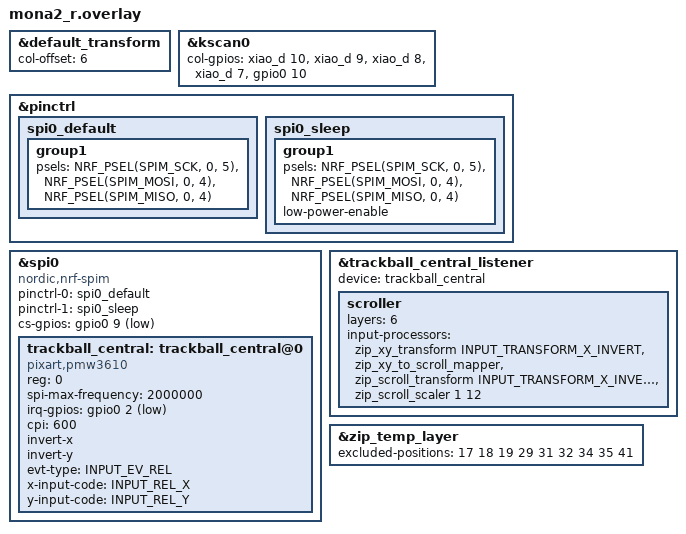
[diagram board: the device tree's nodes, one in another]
#include "mona2.dtsi"
#include <input/processors.dtsi>
#include <zephyr/dt-bindings/input/input-event-codes.h>


&default_transform {
    col-offset = <6>;
};

&kscan0 {
        col-gpios
            = <&xiao_d 10 GPIO_ACTIVE_HIGH>
            , <&xiao_d 9 GPIO_ACTIVE_HIGH> 
            , <&xiao_d 8 GPIO_ACTIVE_HIGH> 
            , <&xiao_d 7 GPIO_ACTIVE_HIGH> 
            , <&gpio0 10 GPIO_ACTIVE_HIGH>
            ;
};


&pinctrl {
    spi0_default: spi0_default {    //通常時(SPI通信中)のピン構成
        group1 {
            psels = <NRF_PSEL(SPIM_SCK, 0, 5)>, //P0.05を指定(SCLK)
                <NRF_PSEL(SPIM_MOSI, 0, 4)>,    //P0.04を指定(SDIOだからMOSI,MISO両方の役割を担う)
                <NRF_PSEL(SPIM_MISO, 0, 4)>;
        };
    };

    spi0_sleep: spi0_sleep {    //スリープ時のピン構成(省電力)
        group1 {
            psels = <NRF_PSEL(SPIM_SCK, 0, 5)>,
                <NRF_PSEL(SPIM_MOSI, 0, 4)>,
                <NRF_PSEL(SPIM_MISO, 0, 4)>;
            low-power-enable;
        };
    };
};


&spi0 {
    status = "okay";
    compatible = "nordic,nrf-spim"; //マイコンがnRFシリーズ
    pinctrl-0 = <&spi0_default>;
    pinctrl-1 = <&spi0_sleep>;
    pinctrl-names = "default", "sleep";
    cs-gpios = <&gpio0 9 GPIO_ACTIVE_LOW>;  //P0.09を指定(CS)

    trackball_central: trackball_central@0 {
        status = "okay";
        compatible = "pixart,pmw3610";  //トラボセンサ用のドライバとバインド
        reg = <0>;
        spi-max-frequency = <2000000>;
        irq-gpios = <&gpio0 2 (GPIO_ACTIVE_LOW | GPIO_PULL_UP)>; //P0.02を指定(MOTION)
        cpi = <600>;
        //swap-xy;
        invert-x; //COROPIT版ではコメントアウトを外す
        invert-y; //COROPIT版ではコメントアウトを外す
        evt-type = <INPUT_EV_REL>;
        x-input-code = <INPUT_REL_X>;
        y-input-code = <INPUT_REL_Y>;
    };
};


// Overrides for the input listener node
&trackball_central_listener {
    status = "okay";
    device = <&trackball_central>;

    // レイヤー6（- 長押し）の間だけ、ボールでスクロールする
    scroller {
        layers = <6>;
        input-processors = 
            // <&zip_xy_transform INPUT_TRANSFORM_XY_SWAP>,        //X軸とY軸の入れ替え
            <&zip_xy_transform INPUT_TRANSFORM_X_INVERT>,       //X軸反転
            <&zip_xy_to_scroll_mapper>,                         //スクロールモードに変更
            <&zip_scroll_transform INPUT_TRANSFORM_X_INVERT>,   //スクロールのX軸反転
            <&zip_scroll_scaler 1 12>;                          //スクロール量を1/12倍（1/5 → 1/10 → 1/12 と遅くした）
    };

};

// オートマウスレイヤー(レイヤー5)の抜け方
// ここに書いたキー以外を押すと、10秒を待たずにすぐレイヤー0に戻る
//   マウス用: 17 18 19 (J K L) / 29 31 (M .)
//   修飾キー: 32 (右⌘) / 34 (⌃) / 35 (左⌥) / 41 (右⌥)  ← ⌘+クリックなどで抜けないように
//   A・Z・- の長押し(⇧ ⌘)は文字も兼ねるので入れない（打つとレイヤー0に戻る）
&zip_temp_layer {
    excluded-positions = <17 18 19 29 31 32 34 35 41>;
};
